# M2354 register map
File version: 1.0
Registers are 32-bit, read-write, reset 0x0 unless marked. A register's access mark holds for its fields unless they carry their own. Offsets are from the block's base; [hi:lo] are bit positions; 'fields as' and 'values as' point back to an identical list.

## CAN_NS — CAN Register Map
Base 0x500A0000
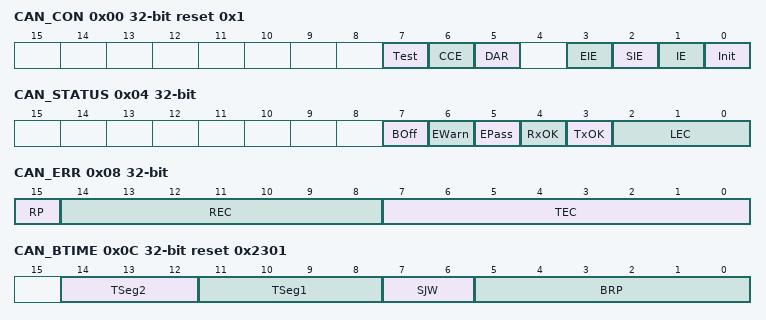
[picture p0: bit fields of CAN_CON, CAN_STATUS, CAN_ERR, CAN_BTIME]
0x00 CAN_CON reset 0x1 — CAN Control Register
  [7] Test — Test Mode Enable Bit
    0=Normal Operation; 1=Test Mode
  [6] CCE — Configuration Change Enable Bit
    0=No write access to the Bit Timing Register; 1=Write access to the Bit Timing Register (CAN_BTIME) allowed. (while Init bit (CAN_CON[0]) = 1)
  [5] DAR — Automatic Re-transmission Disable Bit
    0=Automatic Retransmission of disturbed messages Enabled; 1=Automatic Retransmission Disabled
  [3] EIE — Error Interrupt Enable Bit
    0=Disabled - No Error Status Interrupt will be generated; 1=Enabled - A change in the bits BOff (CAN_STATUS[7]) or EWarn (CAN_STATUS[6]) in the Status Register will generate an interrupt
  [2] SIE — Status Change Interrupt Enable Bit
    0=Disabled - No Status Change Interrupt will be generated; 1=Enabled - An interrupt will be generated when a message transfer is successfully completed or a CAN bus error is detected
  [1] IE — Module Interrupt Enable Bit
    0=Funcrion interrupt Disabled; 1=Funcrion interrupt Enabled
  [0] Init — Init Initialization
    0=Normal Operation; 1=Initialization is started
0x04 CAN_STATUS
  [7] BOff ro — Bus-off Status (Read Only)
    0=The CAN module is not in bus-off state; 1=The CAN module is in bus-off state
  [6] EWarn ro — Error Warning Status (Read Only)
    0=Both error counters are below the error warning limit of 96; 1=At least one of the error counters in the EML has reached the error warning limit of 96
  [5] EPass ro — Error Passive (Read Only)
    0=The CAN Core is error active; 1=The CAN Core is in the error passive state as defined in the CAN Specification
  [4] RxOK — Received a Message Successfully
    0=No message has been successfully received since this bit was last reset by the CPU. This bit is never reset by the CAN Core; 1=A message has been successfully received since this bit was last reset by the CPU (independent of the result of acceptance filtering)
  [3] TxOK — Transmitted a Message Successfully
    0=Since this bit was reset by the CPU, no message has been successfully transmitted. This bit is never reset by the CAN Core; 1=Since this bit was last reset by the CPU, a message has been successfully (error free and acknowledged by at least one other node) transmitted
  [2:0] LEC — Last Error Code. The LEC field holds a code, which indicates the type of the last error to occur on the CAN bus. This field will be cleared to '0' when a message has been transferred (reception or transmission) without error. The unused code '7' may be written by the CPU to check for updates. Table 6.295 Last Error Codedescribes the error code. Note: Type of the Last Error to Occur on the CAN Bus.
0x08 CAN_ERR ro — CAN Error Counter Register
  [15] RP — Receive Error Passive
    0=The Receive Error Counter is below the error passive level; 1=The Receive Error Counter has reached the error passive level as defined in the CAN Specification
  [14:8] REC — Receive Error Counter. Actual state of the Receive Error Counter. Values between 0 and 127.
  [7:0] TEC — Transmit Error Counter. Actual state of the Transmit Error Counter. Values between 0 and 255.
0x0C CAN_BTIME reset 0x2301 — Bit Timing Register
  [14:12] TSeg2 — Time Segment After Sample Point. 0x0-0x7: Valid values for TSeg2 are [0...7]. The actual interpretation by the hardware of this value is such that one more than the value programmed here is used.
  [11:8] TSeg1 — Time Segment Before the Sample Point Minus Sync_Seg. 0x01-0x0F: valid values for TSeg1 are [1...15]. The actual interpretation by the hardware of this value is such that one more than the value programmed is used.
  [7:6] SJW — Synchronization Jump Width. 0x0-0x3: Valid programmed values are [0...3]. The actual interpretation by the hardware of this value is such that one more than the value programmed here is used. Note: It also means re-synchronization jump width.
  [5:0] BRP — Baud Rate Prescaler. 0x01-0x3F: The value by which the oscillator frequency is divided for generating the bit time quanta. The bit time is built up from a multiple of this quanta. Valid values for the Baud Rate Prescaler are [0...63]. The actual interpretation by the hardware of this value is such that one more than the value programmed here is used.
0x10 CAN_IIDR ro — Interrupt Identifier Register
  [15:0] IntId — Interrupt Identifier. These bits indicates the source of the interrupt. If several interrupts are pending, the CAN Interrupt Register will point to the pending interrupt with the highest priority, disregarding their chronological order. An interrupt remains pending until the application software has cleared it. If IntId is different from 0x0000 and IE (CAN_CON[1]) is set, the IRQ interrupt signal to the EIC is active. The interrupt remains active until IntId is back to value 0x0000 (the cause of the interrupt is reset) or until IE is reset. The Status Interrupt has the highest priority. Among the message interrupts, the Message Object' s interrupt priority decreases with increasing message number. A message interrupt is cleared by clearing the Message Object's IntPnd bit (CAN_IFn_MCON[13]). The Status Interrupt is cleared by reading the Status Register.
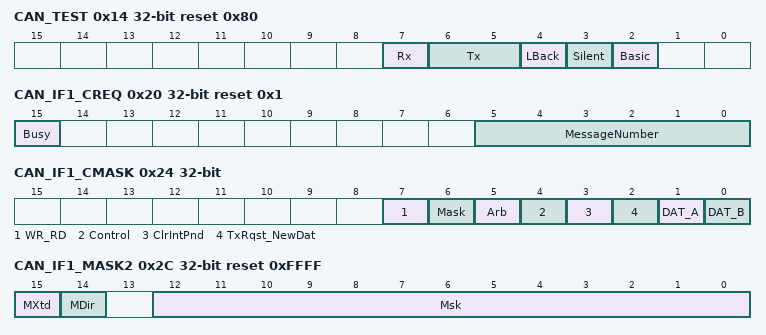
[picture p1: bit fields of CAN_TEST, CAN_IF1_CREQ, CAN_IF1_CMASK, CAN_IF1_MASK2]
0x14 CAN_TEST reset 0x80 — Test Register (Register Map Note 1)
  [7] Rx ro — Monitors the Actual Value of CAN_RX Pin (Read Only). Note: Reset value: 0000 0000 R000 0000 b (R:current value of RX pin)
    0=The CAN bus is dominant (CAN_RX = '0'); 1=The CAN bus is recessive (CAN_RX = '1')
  [6:5] Tx — Tx[1:0]: Control of CAN_TX Pin
    0=Reset value, CAN_TX pin is controlled by the CAN Core; 1=Sample Point can be monitored at CAN_TX pin; 2=CAN_TX pin drives a dominant ('0') value; 3=CAN_TX pin drives a recessive ('1') value
  [4] LBack — Loop Back Mode Enable Bit
    0=Loop Back Mode Disabled; 1=Loop Back Mode Enabled
  [3] Silent — Silent Mode
    0=Normal operation; 1=The module is in Silent Mode
  [2] Basic — Basic Mode
    0=Basic Mode Disabled; 1=IF1 Registers used as Tx Buffer, IF2 Registers used as Rx Buffer
0x18 CAN_BRPE — Baud Rate Prescaler Extension Register
  [3:0] BRPE — Baud Rate Prescaler Extension. 0x00-0x0F: By programming BRPE, the Baud Rate Prescaler can be extended to values up to 1023. The actual interpretation by the hardware is that one more than the value programmed by BRPE (MSBs) and BTIME (LSBs) is used.
0x20 CAN_IF1_CREQ reset 0x1 — IFn (Register Map Note 2) Command Request Registers
  [15] Busy — Busy Flag
    0=Read/write action has finished; 1=Writing to the IFn Command Request Register is in progress. This bit can only be read by the software
  [5:0] MessageNumber — Message Number. 0x01-0x20: Valid Message Number, the Message Object in the Message. RAM is selected for data transfer. 0x00: Not a valid Message Number, interpreted as 0x20. 0x21-0x3F: Not a valid Message Number, interpreted as 0x01-0x1F.
0x24 CAN_IF1_CMASK — IFn Command Mask Registers
  [7] WR_RD — Write or Read Mode
    0=Read: Transfer data from the Message Object addressed by the Command Request Register into the selected Message Buffer Registers; 1=Write: Transfer data from the selected Message Buffer Registers to the Message Object addressed by the Command Request Register
  [6] Mask — Access Mask Bits. Write Operation:
    0=Mask bits unchanged; 1=Transfer Identifier Mask + MDir + MXtd to Message Object. Transfer Identifier Mask + MDir + MXtd to IFn Message Buffer Register
  [5] Arb — Access Arbitration Bits. Write Operation:
    0=Arbitration bits unchanged; 1=Transfer Identifier + Dir (CAN_IFn_ARB2[13]) + Xtd (CAN_IFn_ARB2[14]) + MsgVal (CAN_IFn_ARB2[15]) to Message Object. Transfer Identifier + Dir + Xtd + MsgVal to IFn Message Buffer Register
  [4] Control — Control Access Control Bits. Write Operation:
    0=Control Bits unchanged; 1=Transfer Control Bits to Message Object. Transfer Control Bits to IFn Message Buffer Register
  [3] ClrIntPnd — Clear Interrupt Pending Bit. Write Operation: When writing to a Message Object, this bit is ignored. Read Operation:
    0=IntPnd bit (CAN_IFn_MCON[13]) remains unchanged; 1=Clear IntPnd bit in the Message Object
  [2] TxRqst_NewDat — Access Transmission Request Bit When Write Operation. Note: A read access to a Message Object can be combined with the reset of the control bits IntPnd and NewDat. The values of these bits transferred to the IFn Message Control Register always reflect the status before resetting these bits.
    0=TxRqst bit unchanged. NewDat bit remains unchanged; 1=Set TxRqst bit. Clear NewDat bit in the Message Object
  [1] DAT_A — Access Data Bytes [3:0]. Write Operation:
    0=Data Bytes [3:0] unchanged; 1=Transfer Data Bytes [3:0] to Message Object. Transfer Data Bytes [3:0] to IFn Message Buffer Register
  [0] DAT_B — Access Data Bytes [7:4]. Write Operation:
    0=Data Bytes [7:4] unchanged; 1=Transfer Data Bytes [7:4] to Message Object. Transfer Data Bytes [7:4] to IFn Message Buffer Register
0x28 CAN_IF1_MASK1 reset 0xFFFF — IFn Mask 1 Registers
  [15:0] Msk — Identifier Mask 15-0
    0=The corresponding bit in the identifier of the message object cannot inhibit the match in the acceptance filtering; 1=The corresponding identifier bit is used for acceptance filtering
0x2C CAN_IF1_MASK2 reset 0xFFFF — IFn Mask 2 Registers
  [15] MXtd — Mask Extended Identifier. Note: When 11-bit ('standard') Identifiers are used for a Message Object, the identifiers of received Data Frames are written into bits ID28 to ID18 (CAN_IFn_ARB2[12:2]). For acceptance filtering, only these bits together with mask bits Msk28 to Msk18 (CAN_IFn_MASK2[12:2]) are considered.
    0=The extended identifier bit (IDE) has no effect on the acceptance filtering; 1=The extended identifier bit (IDE) is used for acceptance filtering
  [14] MDir — Mask Message Direction
    0=The message direction bit (Dir (CAN_IFn_ARB2[13])) has no effect on the acceptance filtering; 1=The message direction bit (Dir) is used for acceptance filtering
  [12:0] Msk — Identifier Mask 28-16
    values as CAN_IF1_MASK1.Msk
0x30 CAN_IF1_ARB1 — IFn Arbitration 1 Registers
  [15:0] ID — Message Identifier 15-0. ID28 - ID0, 29-bit Identifier ('Extended Frame'). ID28 - ID18, 11-bit Identifier ('Standard Frame')
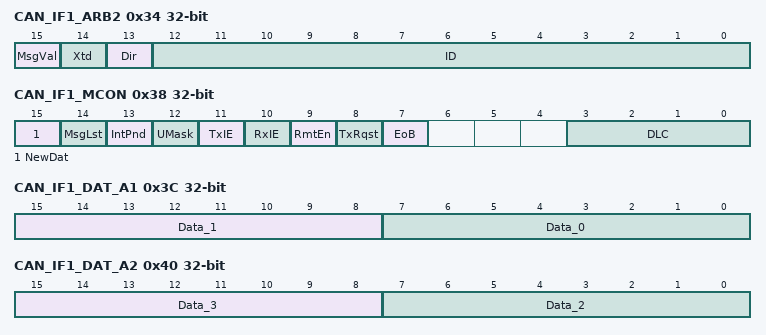
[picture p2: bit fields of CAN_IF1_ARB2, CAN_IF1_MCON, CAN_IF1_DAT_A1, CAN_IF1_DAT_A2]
0x34 CAN_IF1_ARB2 — IFn Arbitration 2 Registers
  [15] MsgVal — Message Valid. Note: The application software must reset the MsgVal bit of all unused Messages Objects during the initialization before it resets bit Init (CAN_CON[0]). This bit must also be reset before the identifier Id28-0 (CAN_IFn_ARB1/2), the control bits Xtd (CAN_IFn_ARB2[14]), Dir (CAN_IFn_ARB2[13]), or the Data Length Code DLC3-0 (CAN_IFn_MCON[3:0]) are modified, or if the Messages Object is no longer required.
    0=The Message Object is ignored by the Message Handler; 1=The Message Object is configured and should be considered by the Message Handler
  [14] Xtd — Extended Identifier
    0=The 11-bit ('standard') Identifier will be used for this Message Object; 1=The 29-bit ('extended') Identifier will be used for this Message Object
  [13] Dir — Message Direction
    0=Direction is receive; 1=Direction is transmit
  [12:0] ID — Message Identifier 28-16. ID28 - ID0, 29-bit Identifier ('Extended Frame'). ID28 - ID18, 11-bit Identifier ('Standard Frame')
0x38 CAN_IF1_MCON — IFn Message Control Registers
  [15] NewDat — New Data
    0=No new data has been written into the data portion of this Message Object by the Message Handler since last time this flag was cleared by the application software; 1=The Message Handler or the application software has written new data into the data portion of this Message Object
  [14] MsgLst — Message Lost
    0=No message lost since last time this bit was reset by the CPU; 1=The Message Handler stored a new message into this object when NewDat was still set, the CPU has lost a message
  [13] IntPnd — Interrupt Pending
    0=This message object is not the source of an interrupt; 1=This message object is the source of an interrupt. The Interrupt Identifier in the Interrupt Register will point to this message object if there is no other interrupt source with higher priority
  [12] UMask — Use Acceptance Mask. Note: If the UMask bit is set to one, the Message Object's mask bits have to be programmed during initialization of the Message Object before MsgVal bit (CAN_IFn_ARB2[15]) is set to one.
    0=Mask ignored; 1=Use Mask (Msk28-0, MXtd, and MDir) for acceptance filtering
  [11] TxIE — Transmit Interrupt Enable Bit
    0=IntPnd (CAN_IFn_MCON[13]) will be left unchanged after the successful transmission of a frame; 1=IntPnd will be set after a successful transmission of a frame
  [10] RxIE — Receive Interrupt Enable Bit
    0=IntPnd (CAN_IFn_MCON[13]) will be left unchanged after a successful reception of a frame; 1=IntPnd will be set after a successful reception of a frame
  [9] RmtEn — Remote Enable Bit
    0=At the reception of a Remote Frame, TxRqst (CAN_IFn_MCON[8]) is left unchanged; 1=At the reception of a Remote Frame, TxRqst is set
  [8] TxRqst — Transmit Request
    0=This Message Object is not waiting for transmission; 1=The transmission of this Message Object is requested and is not yet done
  [7] EoB — End of Buffer. Note: This bit is used to concatenate two or more Message Objects (up to 32) to build a FIFO Buffer. For single Message Objects (not belonging to a FIFO Buffer), this bit must always be set to one.
    0=Message Object belongs to a FIFO Buffer and is not the last Message Object of that FIFO Buffer; 1=Single Message Object or last Message Object of a FIFO Buffer
  [3:0] DLC — Data Length Code. 0-8: Data Frame has 0-8 data bytes. 9-15: Data Frame has 8 data bytes. Note: The Data Length Code of a Message Object must be defined the same as in all the corresponding objects with the same identifier at other nodes. When the Message Handler stores a data frame, it will write the DLC to the value given by the received message. Data(0): 1st data byte of a CAN Data Frame. Data(1): 2nd data byte of a CAN Data Frame. Data(2): 3rd data byte of a CAN Data Frame. Data(3): 4th data byte of a CAN Data Frame. Data(4): 5th data byte of a CAN Data Frame. Data(5): 6th data byte of a CAN Data Frame. Data(6): 7th data byte of a CAN Data Frame. Data(7): 8th data byte of a CAN Data Frame. Note: The Data(0) byte is the first data byte shifted into the shift register of the CAN Core during a reception while the Data(7) byte is the last. When the Message Handler stores a Data Frame, it will write all the eight data bytes into a Message Object. If the Data Length Code is less than 8, the remaining bytes of the Message Object will be overwritten by unspecified values.
0x3C CAN_IF1_DAT_A1 — IFn Data A1 Registers (Register Map Note 3)
  [15:8] Data_1 — Data Byte 1. 2nd data byte of a CAN Data Frame
  [7:0] Data_0 — Data Byte 0. 1st data byte of a CAN Data Frame
0x40 CAN_IF1_DAT_A2 — IFn Data A2 Registers (Register Map Note 3)
  [15:8] Data_3 — Data Byte 3. 4th data byte of CAN Data Frame
  [7:0] Data_2 — Data Byte 2. 3rd data byte of CAN Data Frame
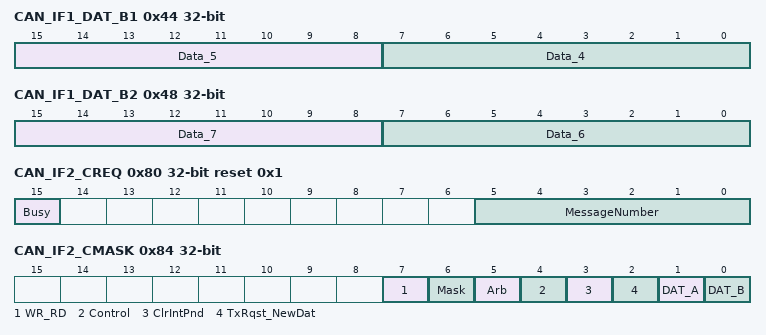
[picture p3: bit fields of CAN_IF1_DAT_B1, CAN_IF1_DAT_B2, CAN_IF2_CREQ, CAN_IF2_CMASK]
0x44 CAN_IF1_DAT_B1 — IFn Data B1 Registers (Register Map Note 3)
  [15:8] Data_5 — Data Byte 5. 6th data byte of CAN Data Frame
  [7:0] Data_4 — Data Byte 4. 5th data byte of CAN Data Frame
0x48 CAN_IF1_DAT_B2 — IFn Data B2 Registers (Register Map Note 3)
  [15:8] Data_7 — Data Byte 7. 8th data byte of CAN Data Frame.
  [7:0] Data_6 — Data Byte 6. 7th data byte of CAN Data Frame.
0x80 CAN_IF2_CREQ reset 0x1 — IFn (Register Map Note 2) Command Request Registers
  fields as CAN_IF1_CREQ
0x84 CAN_IF2_CMASK — IFn Command Mask Registers
  fields as CAN_IF1_CMASK
0x88 CAN_IF2_MASK1 reset 0xFFFF — IFn Mask 1 Registers
  fields as CAN_IF1_MASK1
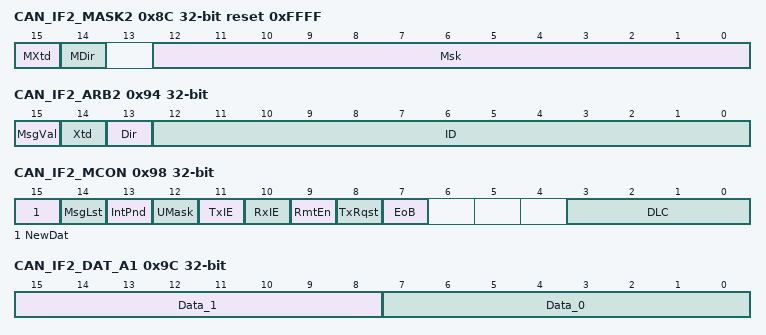
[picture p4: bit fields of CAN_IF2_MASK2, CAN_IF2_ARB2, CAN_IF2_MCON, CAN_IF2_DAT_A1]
0x8C CAN_IF2_MASK2 reset 0xFFFF — IFn Mask 2 Registers
  fields as CAN_IF1_MASK2
0x90 CAN_IF2_ARB1 — IFn Arbitration 1 Registers
  fields as CAN_IF1_ARB1
0x94 CAN_IF2_ARB2 — IFn Arbitration 2 Registers
  fields as CAN_IF1_ARB2
0x98 CAN_IF2_MCON — IFn Message Control Registers
  fields as CAN_IF1_MCON
0x9C CAN_IF2_DAT_A1 — IFn Data A1 Registers (Register Map Note 3)
  fields as CAN_IF1_DAT_A1
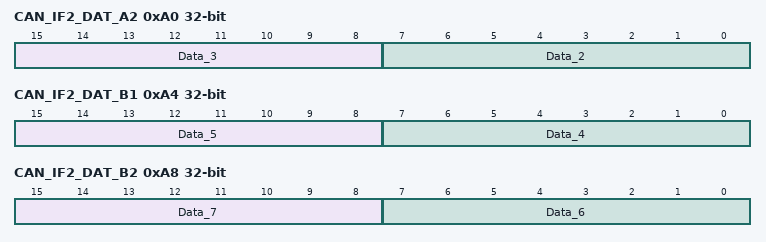
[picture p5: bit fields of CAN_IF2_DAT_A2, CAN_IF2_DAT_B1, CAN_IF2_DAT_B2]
0xA0 CAN_IF2_DAT_A2 — IFn Data A2 Registers (Register Map Note 3)
  fields as CAN_IF1_DAT_A2
0xA4 CAN_IF2_DAT_B1 — IFn Data B1 Registers (Register Map Note 3)
  fields as CAN_IF1_DAT_B1
0xA8 CAN_IF2_DAT_B2 — IFn Data B2 Registers (Register Map Note 3)
  fields as CAN_IF1_DAT_B2
0x100 CAN_TXREQ1 ro — Transmission Request Register 1
  [15:0] TxRqst16_1 — Transmission Request Bits 16-1 of All Message Objects (Read Only)
    values as CAN_IF1_MCON.TxRqst
0x104 CAN_TXREQ2 ro — Transmission Request Register 2
  [15:0] TxRqst32_17 — Transmission Request Bits 32-17 of All Message Objects (Read Only)
    values as CAN_IF1_MCON.TxRqst
0x120 CAN_NDAT1 ro — New Data Register 1
  [15:0] NewData16_1 — New Data Bits 16-1 of All Message Objects
    0=No new data has been written into the data portion of this Message Object by the Message Handler since the last time this flag was cleared by the application software; 1=The Message Handler or the application software has written new data into the data portion of this Message Object
0x124 CAN_NDAT2 ro — New Data Register 2
  [15:0] NewData32_17 — New Data Bits 32-17 of All Message Objects
    values as CAN_NDAT1.NewData16_1
0x140 CAN_IPND1 ro — Interrupt Pending Register 1
  [15:0] IntPnd16_1 — Interrupt Pending Bits 16-1 of All Message Objects
    0=This message object is not the source of an interrupt; 1=This message object is the source of an interrupt
0x144 CAN_IPND2 ro — Interrupt Pending Register 2
  [15:0] IntPnd32_17 — Interrupt Pending Bits 32-17 of All Message Objects
    values as CAN_IPND1.IntPnd16_1
0x160 CAN_MVLD1 ro — Message Valid Register 1
  [15:0] MsgVal16_1 — Message Valid Bits 16-1 of All Message Objects (Read Only). Note: CAN_MVLD1[0] means Message object No.1 is valid or not. If CAN_MVLD1[0] is set, message object No.1 is configured.
    0=This Message Object is ignored by the Message Handler; 1=This Message Object is configured and should be considered by the Message Handler
0x164 CAN_MVLD2 ro — Message Valid Register 2
  [15:0] MsgVal32_17 — Message Valid Bits 32-17 of All Message Objects (Read Only). Note: CAN_MVLD2[15] means Message object No.32 is valid or not. If CAN_MVLD2[15] is set, message object No.32 is configured.
    values as CAN_MVLD1.MsgVal16_1
0x168 CAN_WU_EN — Wake-up Enable Control Register
  [0] WAKUP_EN — Wake-up Enable Bit. Note: User can wake up system when there is a falling edge in the CAN_Rx pin.
    0=The wake-up function Disabled; 1=The wake-up function Enabled
0x16C CAN_WU_STATUS — Wake-up Status Register
  [0] WAKUP_STS — Wake-up Status. Note: This bit can be cleared by writing '0' to it.
    0=No wake-up event occurred; 1=Wake-up event occurred
